VERSION ""

NS_ :

BS_:

BU_: Door RearRight_Node RearLeft_Node FrontRight_Node FrontLeft_Node_ Central_note

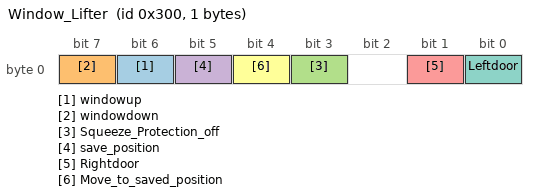
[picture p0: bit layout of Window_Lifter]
BO_ 768 Window_Lifter: 1 Central_note
 SG_ windowup : 6|1@1+ (1,0) [0|0] ""  Door
 SG_ windowdown : 7|1@1+ (1,0) [0|0] ""  Door
 SG_ Squeeze_Protection_off : 3|1@1+ (1,0) [0|0] ""  Door
 SG_ save_position : 5|1@1+ (1,0) [0|0] ""  Door
 SG_ Rightdoor : 1|1@1+ (1,0) [0|0] ""  Door
 SG_ Move_to_saved_position : 4|1@1+ (1,0) [0|0] ""  Door
 SG_ Leftdoor : 0|1@1+ (1,0) [0|0] ""  Door

BO_ 257 TurnRightLamp: 1 Central_note
 SG_ TurnRight : 0|1@1+ (1,0) [0|0] ""  RearRight_Node,FrontRight_Node

BO_ 256 TurnLeftLamp: 1 Central_note
 SG_ TurnLeft : 0|1@1+ (1,0) [0|0] ""  RearLeft_Node,FrontLeft_Node_

EV_ evwindowrestore: 0 [0|1] "" 0 1 DUMMY_NODE_VECTOR0 Vector__XXX;

EV_ evwindowstore: 0 [0|1] "" 0 2 DUMMY_NODE_VECTOR0 Vector__XXX;

EV_ evwindowdown: 0 [0|1] "" 0 3 DUMMY_NODE_VECTOR0 Vector__XXX;

EV_ evwindowup: 0 [0|1] "" 0 4 DUMMY_NODE_VECTOR0 Vector__XXX;

EV_ evRearRight: 0 [0|1] "" 0 5 DUMMY_NODE_VECTOR0 Vector__XXX;

EV_ evFrontRight: 0 [0|1] "" 0 6 DUMMY_NODE_VECTOR0 Vector__XXX;

EV_ evRearLeft: 0 [0|1] "" 0 7 DUMMY_NODE_VECTOR0 Vector__XXX;

EV_ evFrontLeft: 0 [0|1] "" 0 8 DUMMY_NODE_VECTOR0 Vector__XXX;

EV_ evAlarm: 0 [0|1] "" 0 9 DUMMY_NODE_VECTOR0 Vector__XXX;

EV_ evTurnRight: 0 [0|1] "" 0 10 DUMMY_NODE_VECTOR0 Vector__XXX;

EV_ evTurnLeft: 0 [0|1] "" 0 11 DUMMY_NODE_VECTOR0 Vector__XXX;
